# R7KA8P1AD register map
Vendor: Renesas Electronics Corporation; Series: RA8; File version: 1.10.02
CPU: CM85 r0p2, little endian, MPU, FPU, VTOR, 4 interrupt priority bits, 96 interrupts
Registers are 32-bit, read-write, reset 0x0 unless marked. A register's access mark holds for its fields unless they carry their own. Offsets are from the block's base; [hi:lo] are bit positions; {n}, {i} and the like mark numbered series; 'fields as' and 'values as' point back to an identical list.

## ETHA0_NS — Ethernet Agent
Base 0x503CA000
Same registers: ETHA1_NS 0x503CC000
0x00 EAMC reset 0x1 — Mode Configuration Register
  [1:0] OPC — Operating Mode Command
    0=Enter RESET mode; 1=Enter DISABLE mode; 2=Enter CONFIG mode; 3=Enter OPERATION mode
0x04 EAMS ro reset 0x1 — Mode Status Register
  [1:0] OPS — Operating Mode Status Flag
    0=RESET mode; 1=DISABLE mode; 2=CONFIG mode; 3=OPERATION mode
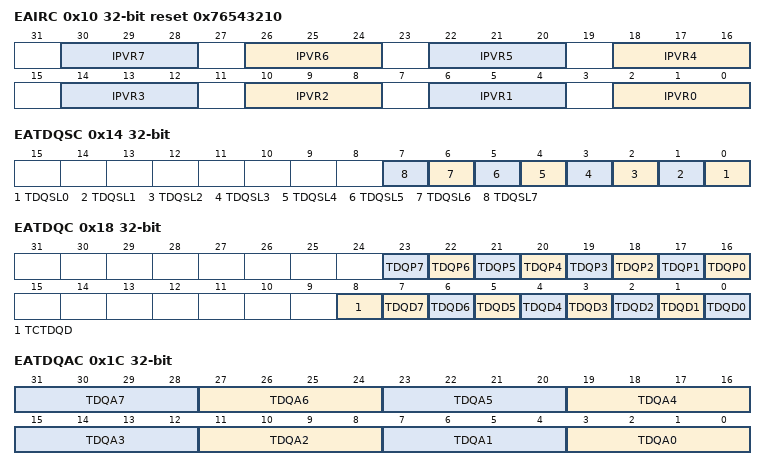
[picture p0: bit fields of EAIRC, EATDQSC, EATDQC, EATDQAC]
0x10 EAIRC reset 0x76543210 — IPV Remapping Configuration Register [802.1Q]
  [4n+2:4n] IPVR{n} (n=0..7) — IPV Remapping {n}
0x14 EATDQSC — TX Descriptor Queue Security Configuration Register
  [all] fields
    0=Queue i unsecure; 1=Queue i secure
  [n] TDQSL{n} (n=0..7) — TX Descriptor Queue n Security Level (n = 0 to 7)
0x18 EATDQC — TX Descriptor Queue Configuration Register
  [n+16] TDQP{n} (n=0..7) — TX Descriptor Queue n Pause (n = 0 to 7)
    0=Queue i active; 1=Queue i paused
  [8] TCTDQD — TX Cut-Through Descriptor Queue Disable
    0=Cut-through queue enabled; 1=Cut-through queue disabled
  [n] TDQD{n} (n=0..7) — TX Descriptor Queue n Disable (n = 0 to 7)
    0=Queue i enabled; 1=Queue i disabled
0x1C EATDQAC — TX Descriptor Queue Arbitration Configuration Register
  [4n+3:4n] TDQA{n} (n=0..7) — TX Descriptor Queue Arbitration {n}
    0=Queue {n} strict arbitration; other=Others (Queue {n} WRR arbitration)
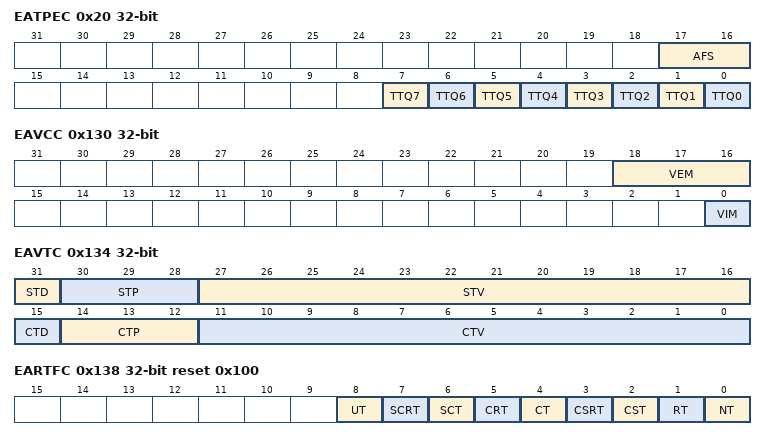
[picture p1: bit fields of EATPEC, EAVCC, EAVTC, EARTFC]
0x20 EATPEC — TX Preemption Configuration Register
  [17:16] AFS — Additional Fragment Size
    0=0 byte is added to minimum fragment size (minimum fragment size = 64 bytes); 1=64 bytes are added to minimum fragment size (minimum fragment size = 128 bytes); 2=128 bytes are added to minimum fragment size (minimum fragment size = 192 bytes); 3=192 bytes are added to minimum fragment size (minimum fragment size = 256 bytes)
  [n] TTQ{n} (n=0..7) — Transmission Type Queue n (n = 0 to 7)
    0=Queue i contains e-frames; 1=Queue i contains p-frames
{0x40+4i} EATMFSC{i} (i=0..7) reset 0xFFFF — Transmission Maximum Frame Size Configuration Register {i}
  [15:0] MFS — Maximum Frame Size
{0x60+4i} EATDQDC{i} (i=0..7) — Transmission Descriptor Queue Depth Configuration Register {i}
  [9:0] DQD — Descriptor Queue Depth
{0x80+4i} EATDQM{i} (i=0..7) ro — Transmission Descriptor Queue {i} Monitoring Register
  [9:0] DNQ — Descriptor Number in Queue
{0xA0+4i} EATDQMLM{i} (i=0..7) ro — Transmission Descriptor Queue {i} Max Level Monitoring Register
  [9:0] DMLQ — Descriptor Max Level in Queue
0x100 EACTQC — Cut-Through Queue Configuration Register
  [15:0] CTQD — Cut-Through Queue Delay (clk Cycle Number)
0x104 EACTDQDC — Cut-Through Descriptor Queue Depth Configuration Register
  [3:0] CTDQD — Cut-Through Descriptor Queue Depth
0x108 EACTDQM ro — Cut-Through Descriptor Queue Monitoring Register
  [3:0] CTQDN — Cut-Though Queue Descriptor Number
0x10C EACTDQMLM ro — Cut-Through Descriptor Queue Max Level Monitoring Register
  [3:0] CTDMLQ — Cut-Through Descriptor Max Level in Queue
0x130 EAVCC — VLAN Control Configuration Register
  [18:16] VEM — VLAN Egress Mode
    0=No VLAN mode; 1=C-TAG VLAN mode; 2=HW C-TAG VLAN mode; 3=SC-TAG VLAN mode; 4=HW SC-TAG VLAN mode
  [0] VIM — VLAN Ingress Mode
    0=Incoming VLAN mode; 1=Port based VLAN mode
0x134 EAVTC — VLAN TAG Configuration Register
  [31] STD — S-TAG DEI
  [30:28] STP — S-TAG PCP
  [27:16] STV — S-TAG VLAN
  [15] CTD — C-TAG DEI
  [14:12] CTP — C-TAG PCP
  [11:0] CTV — C-TAG VLAN
0x138 EARTFC reset 0x100 — Reception TAG Filtering Configuration Register
  [8] UT — Unknown TAG
    0=Unknown TAG frame passed; 1=Unknown TAG frame rejected
  [7] SCRT — SCR-TAG
    0=SCR-TAG frame passed; 1=SCR-TAG frame rejected
  [6] SCT — SC-TAG
    0=SC-TAG frame passed; 1=SC-TAG frame rejected
  [5] CRT — CR-TAG
    0=CR-TAG frame passed; 1=CR-TAG frame rejected
  [4] CT — C-TAG
    0=C-TAG frame passed; 1=C-TAG frame rejected
  [3] CSRT — CoSR-TAG
    0=CoSR-TAG frame passed; 1=CoSR-TAG frame rejected
  [2] CST — CoS-TAG
    0=CoS-TAG frame passed; 1=CoS-TAG frame rejected
  [1] RT — R-TAG
    0=R-TAG frame passed; 1=R-TAG frame rejected
  [0] NT — No TAG
    0=No TAG frame passed; 1=No TAG frame rejected
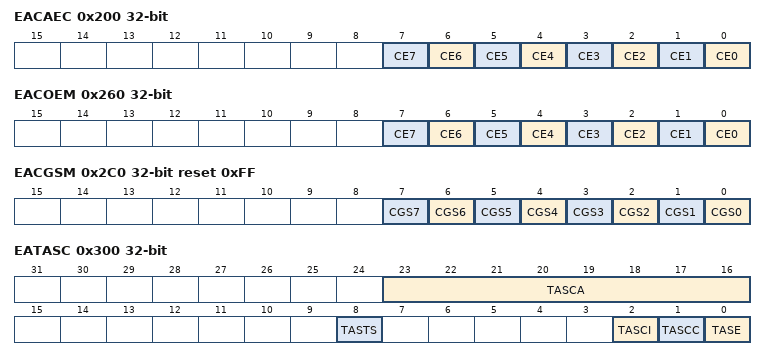
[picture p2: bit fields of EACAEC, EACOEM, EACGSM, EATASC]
0x200 EACAEC — CBS Admin Enable Configuration Register
  [all] fields
    0=CBS for descriptor queue i disabled; 1=CBS for descriptor queue i enabled
  [n] CE{n} (n=0..7) — CBS Enable n (n = 0 to 7)
0x204 EACC — CBS Configuration Register
  [7:0] CC7 to CC0 wo — Configuration Change n (n = 0 to 7)
    0=No effect; 1=The Admin settings of CBS i are copied to its Oper settings (EACAEC.CEi, EACAIVCq.CIV, and EACAULCq.CUL are respectively copied to EACOEM.CEi, EACOIVMq.CIV, and EACOULMq.CUL)
{0x220+4i} EACAIVC{i} (i=0..7) — CBS Admin Increment Value Configuration Register {i}
  [19:0] CIV — Credit Increment Value
0x240 EACAULCq reset 0x7FFFFFFF — CBS Admin Upper Limit Configuration Register q
  [30:0] CUL — Credit Upper Limit
0x260 EACOEM ro — CBS Oper Enable Monitoring Register
  fields as EACAEC
{0x280+4i} EACOIVM{i} (i=0..7) ro — CBS Oper Increment Value Monitoring Register {i}
  [19:0] CIV — Credit Increment Value
{0x2A0+4i} EACOULM{i} (i=0..7) ro reset 0x7FFFFFFF — CBS Oper Upper Limit Monitoring Register {i}
  [30:0] CUL — Credit Upper Limit
0x2C0 EACGSM ro reset 0xFF — CBS Gate State Monitoring Register
  [all] fields
    0=CBS does not authorize queue i transmission (CBS credit negative); 1=CBS authorizes queue i transmission (CBS credit positive)
  [n] CGS{n} (n=0..7) — CBS Gate State n (n = 0 to 7)
0x300 EATASC — TAS Configuration Register
  [23:16] TASCA ro — TAS Configuration Address
  [8] TASTS — TAS Timer Select
  [2] TASCI ro — TAS Configuration Impossible
    0=TAS configuration is possible; 1=TAS configuration is not possible
  [1] TASCC — TAS Configuration Change
    0=TAS is not changing configuration; 1=TAS is changing configuration
  [0] TASE — TAS Enable
    0=TAS disabled; 1=TAS enabled
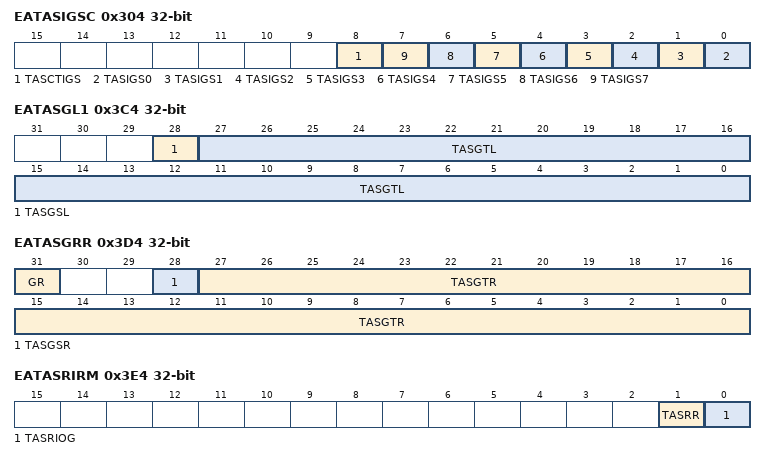
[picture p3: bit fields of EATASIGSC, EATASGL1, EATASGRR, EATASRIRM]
0x304 EATASIGSC — TAS Initial Gate State Configuration Register
  [all] fields
    0=Initial gate state is closed; 1=Initial gate state is opened
  [8] TASCTIGS — TAS Cut-Through Initial Gate State
  [n] TASIGS{n} (n=0..7) — TAS Initial Gate State n (n = 0 to 7)
{0x320+4i} EATASENC{i} (i=0..7) — TAS Entry Number Configuration Register {i}
  [8:0] TASAEN — TAS Admin Entry Number
0x340 EATASCTENC — TAS Cut-Through Entry Number Configuration Register
  [8:0] TASCTAEN — TAS Admin Cut-Through Entry Number
{0x360+4i} EATASENM{i} (i=0..7) ro — TAS Entry Number Monitoring Register {i}
  [8:0] TASOEN — TAS Oper Entry Number
0x380 EATASCTENM ro — TAS Cut-Through Entry Number Monitoring Register
  [8:0] TASCTOEN — TAS Cut-Through Oper Entry Number
0x3A0 EATASCSTC0 — TAS Cycle Start Time Configuration Register 0
  [31:0] TASACSTP0 — TAS Admin Cycle Start Time Part 0
0x3A4 EATASCSTC1 — TAS Cycle Start Time Configuration Register 1
  [31:0] TASACSTP1 — TAS Admin Cycle Start Time Part 1
0x3A8 EATASCSTM0 ro — TAS Cycle Start Time Monitoring Register 0
  [31:0] TASOCSTP0 — TAS Oper Cycle Start Time Part 0
0x3AC EATASCSTM1 ro — TAS Cycle Start Time Monitoring Register 1
  [31:0] TASOCSTP1 — TAS Oper Cycle Start Time Part 1
0x3B0 EATASCTC — TAS Cycle Time Configuration Register
  [31:0] TASACT — TAS Admin Cycle Time
0x3B4 EATASCTM ro — TAS Cycle Time Monitoring Register
  [31:0] TASOCT — TAS Oper Cycle Time
0x3C0 EATASGL0 — TAS Gate Learn Register 0
  [7:0] TASGAL — TAS Gate Address Learn
0x3C4 EATASGL1 — TAS Gate Learn Register 1
  [28] TASGSL — TAS Gate State Learn
  [27:0] TASGTL — TAS Gate Time Learn
0x3C8 EATASGLR ro — TAS Gate Learn Result Register
  [31] GL — Gate Learn
0x3D0 EATASGR — TAS Gate Read Register
  [7:0] TASGAR — TAS Gate Address Read
0x3D4 EATASGRR ro — TAS Gate Read Result Register
  [31] GR — Gate Read
  [28] TASGSR — TAS Gate State Read
  [27:0] TASGTR — TAS Gate Time Read
0x3E0 EATASHCC — TAS Hardware Calibration Configuration Register
  [15:0] TASJ — TAS Jitter
0x3E4 EATASRIRM — TAS RAM Initialization Register Monitoring Register
  [1] TASRR ro — TAS RAM Ready
  [0] TASRIOG — TAS RAM Initialization Ongoing
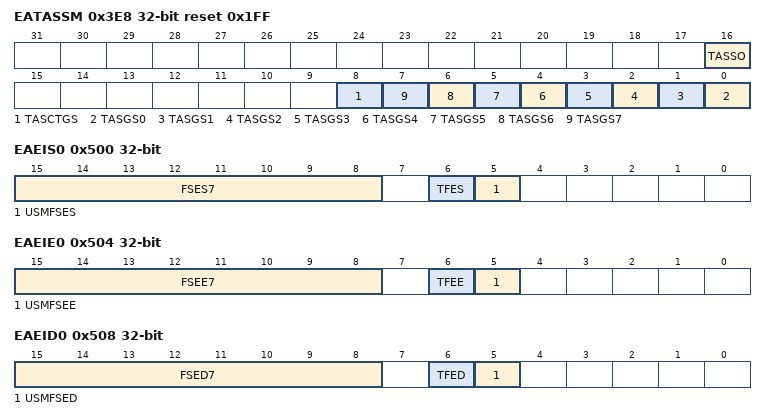
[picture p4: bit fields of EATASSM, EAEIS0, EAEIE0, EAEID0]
0x3E8 EATASSM ro reset 0x1FF — TAS Status Monitoring Register
  [16] TASSO — TAS Scheduler Ongoing
    0=TAS scheduler is not ongoing; 1=TAS scheduler is ongoing
  [8] TASCTGS — TAS Cut-Through Gate State
    0=Cut-through gate is closed; 1=Cut-through gate is opened
  [n] TASGS{n} (n=0..7) — TAS Gate n State (n = 0 to 7)
    0=Gate i is closed; 1=Gate i is opened
0x400 EAUSMFSECN ro — Under Minimum Frame Size Error Counter Register
  [15:0] USMFSEN — Under Minimum Frame Size Error Number
0x404 EATFECN ro — TAG Filtering Error Counter Register
  [15:0] TFEN — TAG Filtering Error Number
0x408 EAFSECN ro — Frame Size Error Counter Register
  [15:0] FSEN — Frame Size Error Number
0x40C EADQOECN ro — Descriptor Queue Overflow Error Counter Register
  [15:0] DQOEN — Descriptor Queue Overflow Error Number
0x410 EADQSECN ro — Descriptor Queue Security Error Counter Register
  [15:0] DQSEN — Descriptor Queue Security Error Number
0x500 EAEIS0 — Error Interrupt Status Register 0
  [15:8] FSES7 to FSES0 — Frame Size Error Status Flag n (n = 0 to 7)
  [6] TFES — TAG Filtering Error Status Flag
  [5] USMFSES — Under Switch Minimum Frame Size Error Status Flag
0x504 EAEIE0 — Error Interrupt Enable Register 0
  [15:8] FSEE7 to FSEE0 — Frame Size Error Enable n (n = 0 to 7)
    0=Interrupt disabled for descriptor queue i; 1=Interrupt enabled for descriptor queue i
  [6] TFEE — TAG Filtering Error Enable
    0=Interrupt disabled; 1=Interrupt enabled
  [5] USMFSEE — Under Switch Minimum Frame Size Error Enable
    0=Interrupt disabled; 1=Interrupt enabled
0x508 EAEID0 ro — Error Interrupt Disable Register 0
  [15:8] FSED7 to FSED0 — Frame Size Error Disable n (n = 0 to 7)
  [6] TFED — TAG Filtering Error Disable
  [5] USMFSED — Under Switch Minimum Frame Size Error Disable
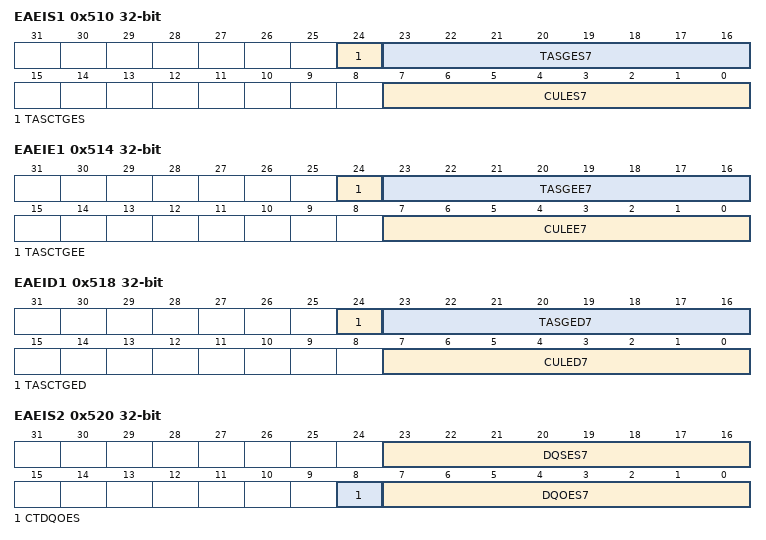
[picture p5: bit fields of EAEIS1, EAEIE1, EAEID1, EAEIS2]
0x510 EAEIS1 — Error Interrupt Status Register 1
  [24] TASCTGES — TAS Cut-Through Gate Error Status Flag
  [23:16] TASGES7 to TASGES0 — TAS Gate n Error Status Flag (n = 0 to 7)
  [7:0] CULES7 to CULES0 — CBS n Upper Limit Error Status Flag (n = 0 to 7)
0x514 EAEIE1 — Error Interrupt Enable Register 1
  [24] TASCTGEE — TAS Cut-through Gate Error Enable
    0=Interrupt disabled; 1=Interrupt enabled
  [23:16] TASGEE7 to TASGEE0 — TAS Gate n Error Enable (n = 0 to 7)
    values as EAEIE0.FSEE7
  [7:0] CULEE7 to CULEE0 — CBS n Upper Limit Error Enable (n = 0 to 7)
    values as EAEIE0.FSEE7
0x518 EAEID1 ro — Error Interrupt Disable Register 1
  [24] TASCTGED — TAS Cut-through Gate Error Disable
  [23:16] TASGED7 to TASGED0 — TAS Gate n Error Disable (n = 0 to 7)
  [7:0] CULED7 to CULED0 — CBS n Upper Limit Error Disable (n = 0 to 7)
0x520 EAEIS2 — Error Interrupt Status Register 2
  [23:16] DQSES7 to DQSES0 — Descriptor Queue n Security Error Status Flag (n = 0 to 7)
  [8] CTDQOES — Cut-Through Descriptor Queue Overflow Error Status Flag
  [7:0] DQOES7 to DQOES0 — Descriptor Queue n Overflow Error Status Flag (n = 0 to 7)
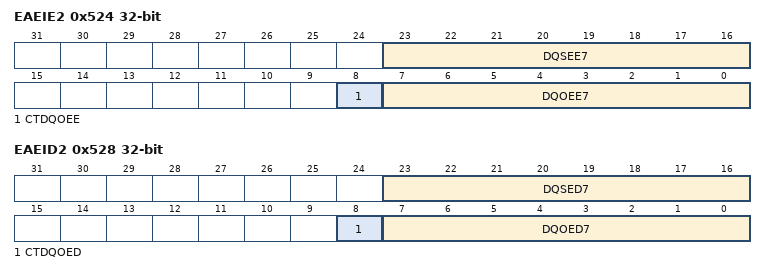
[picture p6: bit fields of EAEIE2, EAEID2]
0x524 EAEIE2 — Error Interrupt Enable Register 2
  [23:16] DQSEE7 to DQSEE0 — Descriptor Queue n Security Error Enable (n = 0 to 7)
    values as EAEIE0.FSEE7
  [8] CTDQOEE — Cut-Through Descriptor Queue Overflow Error Enable
    0=Interrupt disabled; 1=Interrupt enabled
  [7:0] DQOEE7 to DQOEE0 — Descriptor Queue n Overflow Error Enable (n = 0 to 7)
    values as EAEIE0.FSEE7
0x528 EAEID2 ro — Error Interrupt Disable Register 2
  [23:16] DQSED7 to DQSED0 — Descriptor Queue n Security Error Disable (n = 0 to 7)
  [8] CTDQOED — Cut-Through Descriptor Queue Overflow Error Disable
  [7:0] DQOED7 to DQOED0 — Descriptor Queue n Overflow Error Disable (n = 0 to 7)
